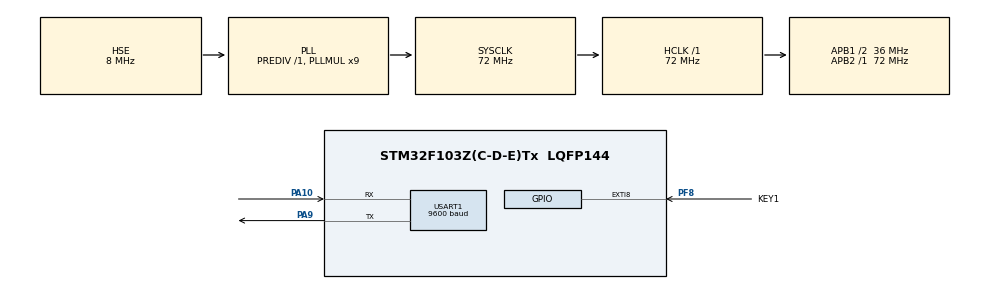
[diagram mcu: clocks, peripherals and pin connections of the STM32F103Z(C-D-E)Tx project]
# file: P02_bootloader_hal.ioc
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Mcu.Family=STM32F1
Mcu.Name=STM32F103Z(C-D-E)Tx
Mcu.Package=LQFP144
NVIC.EXTI9_5_IRQn=true\:4\:0\:true\:false\:true\:true\:true\:true
NVIC.PriorityGroup=NVIC_PRIORITYGROUP_4
NVIC.USART1_IRQn=true\:5\:0\:true\:false\:true\:true\:true\:true
OSC_IN.Mode=HSE-External-Oscillator
OSC_IN.Signal=RCC_OSC_IN
OSC_OUT.Mode=HSE-External-Oscillator
OSC_OUT.Signal=RCC_OSC_OUT
PA10.Mode=Asynchronous
PA10.Signal=USART1_RX
PA13.Mode=Serial_Wire
PA13.Signal=SYS_JTMS-SWDIO
PA14.Mode=Serial_Wire
PA14.Signal=SYS_JTCK-SWCLK
PA9.Mode=Asynchronous
PA9.Signal=USART1_TX
PC14-OSC32_IN.Mode=LSE-External-Oscillator
PC14-OSC32_IN.Signal=RCC_OSC32_IN
PC15-OSC32_OUT.Mode=LSE-External-Oscillator
PC15-OSC32_OUT.Signal=RCC_OSC32_OUT
PF8.GPIO_Label=KEY1
PF8.GPIO_ModeDefaultEXTI=GPIO_MODE_IT_FALLING
PF8.GPIO_PuPd=GPIO_PULLUP
PF8.Signal=GPXTI8
ProjectManager.HeapSize=0x200
ProjectManager.StackSize=0x400
ProjectManager.TargetToolchain=MDK-ARM V5.32
RCC.AHBFreq_Value=72000000
RCC.APB1CLKDivider=RCC_HCLK_DIV2
RCC.APB1Freq_Value=36000000
RCC.APB1TimFreq_Value=72000000
RCC.APB2Freq_Value=72000000
RCC.APB2TimFreq_Value=72000000
RCC.HCLKFreq_Value=72000000
RCC.PLLMUL=RCC_PLL_MUL9
RCC.PLLSourceVirtual=RCC_PLLSOURCE_HSE
RCC.SYSCLKFreq_VALUE=72000000
RCC.SYSCLKSource=RCC_SYSCLKSOURCE_PLLCLK
RCC.USBFreq_Value=72000000
USART1.BaudRate=9600
USART1.VirtualMode=VM_ASYNC
board=custom

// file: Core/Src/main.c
/* USER CODE BEGIN Header */
/**
 ******************************************************************************
 * @file           : main.c
 * @brief          : Main program body
 ******************************************************************************
 * @attention
 *
 * Copyright (c) 2026 STMicroelectronics.
 * All rights reserved.
 *
 * This software is licensed under terms that can be found in the LICENSE file
 * in the root directory of this software component.
 * If no LICENSE file comes with this software, it is provided AS-IS.
 *
 ******************************************************************************
 */
/* USER CODE END Header */
#include "main.h"
#include "usart.h"
#include "gpio.h"

/* USER CODE BEGIN Includes */
#include "App_bootloader.h"
/* USER CODE END Includes */

void SystemClock_Config(void);
/* USER CODE BEGIN PFP */
extern uint16_t uart_rec_full_len;
/* USER CODE END PFP */

/* USER CODE BEGIN 0 */
// #define REC_BUFF_LEN 512

/* USER CODE END 0 */

int main(void)
{

  /* MCU Configuration--------------------------------------------------------*/

  /* Reset of all peripherals, Initializes the Flash interface and the Systick. */
  HAL_Init();

  /* Configure the system clock */
  SystemClock_Config();

  /* Initialize all configured peripherals */
  MX_GPIO_Init();
  MX_USART1_UART_Init();
  /* USER CODE BEGIN 2 */
  // uint8_t receive_buff[REC_BUFF_LEN] = {0};
  // uint16_t receive_len = 0;
  // Int_bootloader_init();

  // 测试应用层逻辑
  App_bootloader_init();

  /* USER CODE END 2 */

  /* Infinite loop */
  /* USER CODE BEGIN WHILE */
  while (1)
  {
    // 1: 串口编号 句柄  2: 接收缓冲区  3: 缓冲区大小 4: 超时时间
    // 代码需要挂起等待 => 1. 接收的缓冲区满了  2. 接收的时间超时
    // HAL_UART_Receive(&huart1,receive_buff,REC_BUFF_LEN,0xffffff);

    // 特殊函数  =>  退出挂起等待 => idle空闲帧模式 => 额外填写一个地址值存储接收数据的长度
    // 1: 串口编号 句柄  2: 接收缓冲区  3: 缓冲区大小 4:实际接收到数据的长度(地址值) 5: 超时时间
    // 缓冲区大小不足  会造成单次接收数据丢失   =>  设计者考虑单次发送的数据  缓冲区能够接收下的才行
    // 业内常用的配置 单次接收缓冲区256字节
    // HAL_UARTEx_ReceiveToIdle(&huart1, receive_buff, REC_BUFF_LEN, &receive_len, 0xffffff);

    // if (receive_len > 0)
    // {
    //   // 1: 串口编号 句柄  2: 数据  3: 数据长度
    //   HAL_UART_Transmit(&huart1, receive_buff, strlen((char *)receive_buff), 1000);
    //   memset(receive_buff, 0, REC_BUFF_LEN);
    //   receive_len = 0;
    // }
    // printf("%d\r\n", uart_rec_full_len);
    // HAL_Delay(3000);
    // Int_bootloader_jump_to_app();

    App_bootloader_work();

    /* USER CODE END WHILE */

  }
}

void SystemClock_Config(void)
{
  RCC_OscInitTypeDef RCC_OscInitStruct = {0};
  RCC_ClkInitTypeDef RCC_ClkInitStruct = {0};

  /** Initializes the RCC Oscillators according to the specified parameters
  * in the RCC_OscInitTypeDef structure.
  */
  RCC_OscInitStruct.OscillatorType = RCC_OSCILLATORTYPE_HSE;
  RCC_OscInitStruct.HSEState = RCC_HSE_ON;
  RCC_OscInitStruct.HSEPredivValue = RCC_HSE_PREDIV_DIV1;
  RCC_OscInitStruct.HSIState = RCC_HSI_ON;
  RCC_OscInitStruct.PLL.PLLState = RCC_PLL_ON;
  RCC_OscInitStruct.PLL.PLLSource = RCC_PLLSOURCE_HSE;
  RCC_OscInitStruct.PLL.PLLMUL = RCC_PLL_MUL9;
  if (HAL_RCC_OscConfig(&RCC_OscInitStruct) != HAL_OK)
  {
    Error_Handler();
  }

  /** Initializes the CPU, AHB and APB buses clocks
  */
  RCC_ClkInitStruct.ClockType = RCC_CLOCKTYPE_HCLK|RCC_CLOCKTYPE_SYSCLK
                              |RCC_CLOCKTYPE_PCLK1|RCC_CLOCKTYPE_PCLK2;
  RCC_ClkInitStruct.SYSCLKSource = RCC_SYSCLKSOURCE_PLLCLK;
  RCC_ClkInitStruct.AHBCLKDivider = RCC_SYSCLK_DIV1;
  RCC_ClkInitStruct.APB1CLKDivider = RCC_HCLK_DIV2;
  RCC_ClkInitStruct.APB2CLKDivider = RCC_HCLK_DIV1;

  if (HAL_RCC_ClockConfig(&RCC_ClkInitStruct, FLASH_LATENCY_2) != HAL_OK)
  {
    Error_Handler();
  }
}

void Error_Handler(void)
{
  __disable_irq();
  while (1)
  {
  }
}
